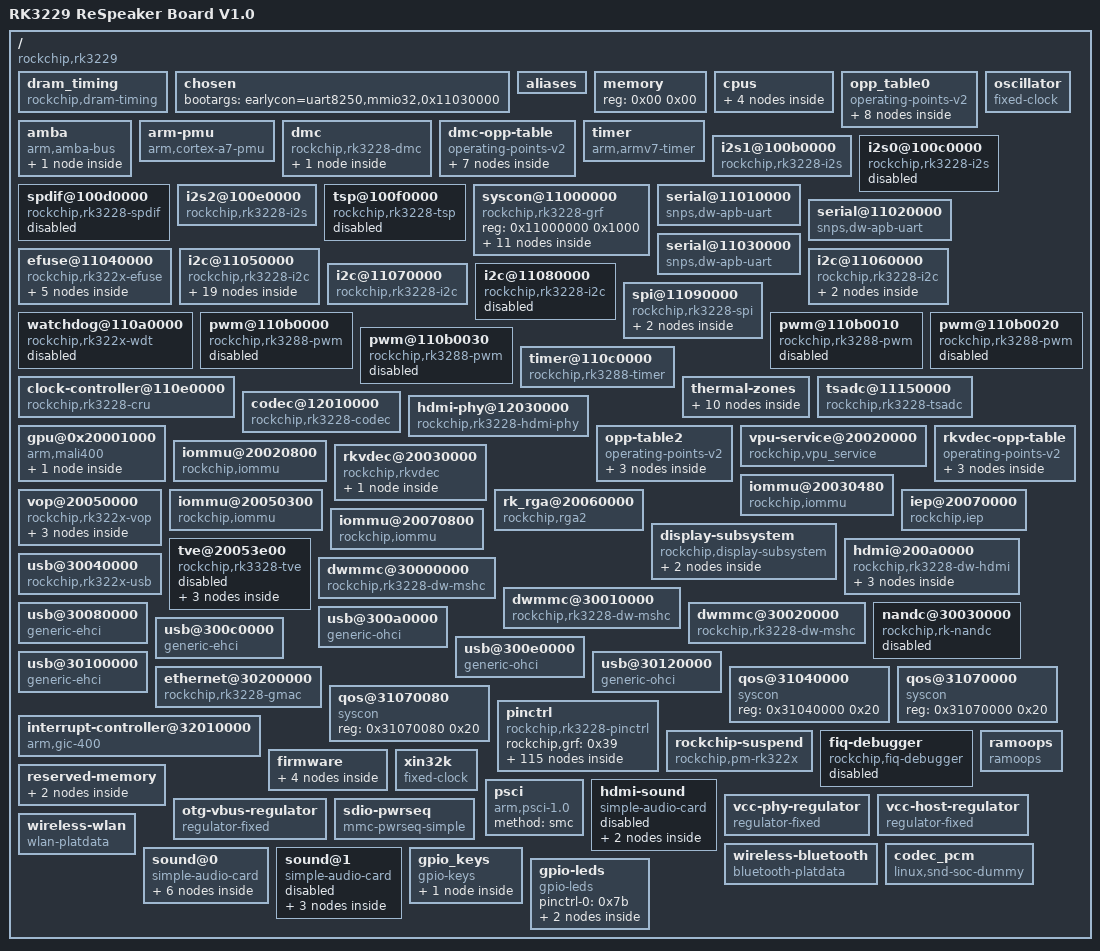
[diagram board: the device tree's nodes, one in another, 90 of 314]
/dts-v1/;

/ {
	#address-cells = <0x01>;
	#size-cells = <0x01>;
	interrupt-parent = <0x01>;
	model = "RK3229 ReSpeaker Board V1.0";
	compatible = "rockchip,rk3229";

	dram_timing {
		compatible = "rockchip,dram-timing";
		dram_spd_bin = <0x15>;
		sr_idle = <0x18>;
		pd_idle = <0x20>;
		dram_dll_disb_freq = <0x12c>;
		phy_dll_disb_freq = <0x190>;
		dram_odt_disb_freq = <0x14d>;
		phy_odt_disb_freq = <0x14d>;
		ddr3_drv = <0x00>;
		ddr3_odt = <0x40>;
		lpddr3_drv = <0x01>;
		lpddr3_odt = <0x03>;
		lpddr2_drv = <0x01>;
		phy_ddr3_clk_drv = <0x12>;
		phy_ddr3_cmd_drv = <0x12>;
		phy_ddr3_dqs_drv = <0x15>;
		phy_ddr3_odt = <0x02>;
		phy_lp23_clk_drv = <0x13>;
		phy_lp23_cmd_drv = <0x16>;
		phy_lp23_dqs_drv = <0x16>;
		phy_lp3_odt = <0x02>;
		phandle = <0x0b>;
	};

	chosen {
		bootargs = "earlycon=uart8250,mmio32,0x11030000";
	};

	aliases {
		serial0 = "/serial@11010000";
		serial1 = "/serial@11020000";
		serial2 = "/serial@11030000";
		spi0 = "/spi@11090000";
	};

	memory {
		device_type = "memory";
		reg = <0x00 0x00>;
	};

	cpus {
		#address-cells = <0x01>;
		#size-cells = <0x00>;

		cpu@f00 {
			device_type = "cpu";
			compatible = "arm,cortex-a7";
			reg = <0xf00>;
			resets = <0x02 0x04>;
			operating-points-v2 = <0x03>;
			#cooling-cells = <0x02>;
			dynamic-power-coefficient = <0x7a>;
			clock-latency = <0x9c40>;
			clocks = <0x02 0x05>;
			enable-method = "psci";
			cpu-supply = <0x04>;
			phandle = <0x06>;
		};

		cpu@f01 {
			device_type = "cpu";
			compatible = "arm,cortex-a7";
			reg = <0xf01>;
			resets = <0x02 0x05>;
			operating-points-v2 = <0x03>;
			enable-method = "psci";
			phandle = <0x07>;
		};

		cpu@f02 {
			device_type = "cpu";
			compatible = "arm,cortex-a7";
			reg = <0xf02>;
			resets = <0x02 0x06>;
			operating-points-v2 = <0x03>;
			enable-method = "psci";
			phandle = <0x08>;
		};

		cpu@f03 {
			device_type = "cpu";
			compatible = "arm,cortex-a7";
			reg = <0xf03>;
			resets = <0x02 0x07>;
			operating-points-v2 = <0x03>;
			enable-method = "psci";
			phandle = <0x09>;
		};
	};

	opp_table0 {
		compatible = "operating-points-v2";
		opp-shared;
		clocks = <0x02 0x01>;
		rockchip,max-volt = <0x149970>;
		rockchip,leakage-voltage-sel = <0x01 0x08 0x00 0x09 0xfe 0x01>;
		nvmem-cells = <0x05>;
		nvmem-cell-names = "cpu_leakage";
		phandle = <0x03>;

		opp-408000000 {
			opp-hz = <0x00 0x18519600>;
			opp-microvolt = <0xe7ef0 0xe7ef0 0x155cc0>;
			opp-microvolt-L0 = <0xe7ef0 0xe7ef0 0x155cc0>;
			opp-microvolt-L1 = <0xe7ef0 0xe7ef0 0x155cc0>;
			clock-latency-ns = <0x9c40>;
			opp-suspend;
		};

		opp-600000000 {
			opp-hz = <0x00 0x23c34600>;
			opp-microvolt = <0xee098 0xee098 0x155cc0>;
			opp-microvolt-L0 = <0xee098 0xee098 0x155cc0>;
			opp-microvolt-L1 = <0xee098 0xee098 0x155cc0>;
		};

		opp-816000000 {
			opp-hz = <0x00 0x30a32c00>;
			opp-microvolt = <0xf4240 0xf4240 0x155cc0>;
			opp-microvolt-L0 = <0xf4240 0xf4240 0x155cc0>;
			opp-microvolt-L1 = <0xf4240 0xf4240 0x155cc0>;
		};

		opp-1008000000 {
			opp-hz = <0x00 0x3c14dc00>;
			opp-microvolt = <0x11edd8 0x11edd8 0x155cc0>;
			opp-microvolt-L0 = <0x11edd8 0x11edd8 0x155cc0>;
			opp-microvolt-L1 = <0x112a88 0x112a88 0x155cc0>;
		};

		opp-1200000000 {
			opp-hz = <0x00 0x47868c00>;
			opp-microvolt = <0x137478 0x137478 0x155cc0>;
			opp-microvolt-L0 = <0x137478 0x137478 0x155cc0>;
			opp-microvolt-L1 = <0x12b128 0x12b128 0x155cc0>;
		};

		opp-1296000000 {
			opp-hz = <0x00 0x4d3f6400>;
			opp-microvolt = <0x1437c8 0x1437c8 0x155cc0>;
			opp-microvolt-L0 = <0x1437c8 0x1437c8 0x155cc0>;
			opp-microvolt-L1 = <0x137478 0x137478 0x155cc0>;
		};

		opp-1392000000 {
			opp-hz = <0x00 0x52f83c00>;
			opp-microvolt = <0x149970 0x149970 0x155cc0>;
			opp-microvolt-L0 = <0x149970 0x149970 0x155cc0>;
			opp-microvolt-L1 = <0x1437c8 0x1437c8 0x155cc0>;
		};

		opp-1464000000 {
			opp-hz = <0x00 0x5742de00>;
			opp-microvolt = <0x155cc0 0x155cc0 0x155cc0>;
			opp-microvolt-L0 = <0x155cc0 0x155cc0 0x155cc0>;
			opp-microvolt-L1 = <0x149970 0x149970 0x155cc0>;
		};
	};

	amba {
		compatible = "arm,amba-bus";
		#address-cells = <0x01>;
		#size-cells = <0x01>;
		ranges;

		pdma@110f0000 {
			compatible = "arm,pl330", "arm,primecell";
			reg = <0x110f0000 0x4000>;
			interrupts = <0x00 0x00 0x04 0x00 0x01 0x04>;
			#dma-cells = <0x01>;
			clocks = <0x02 0xc2>;
			clock-names = "apb_pclk";
			peripherals-req-type-burst;
			phandle = <0x0e>;
		};
	};

	arm-pmu {
		compatible = "arm,cortex-a7-pmu";
		interrupts = <0x00 0x4c 0x04 0x00 0x4d 0x04 0x00 0x4e 0x04 0x00 0x4f 0x04>;
		interrupt-affinity = <0x06 0x07 0x08 0x09>;
	};

	dmc {
		compatible = "rockchip,rk3228-dmc", "rockchip,rk322x-dram";
		clocks = <0x02 0x90>;
		clock-names = "dmc_clk";
		operating-points-v2 = <0x0a>;
		system-status-freq = <0x01 0x927c0 0x10 0xa2990 0x10000 0xbfe50>;
		dram_freq = <0x2ed96880>;
		rockchip,dram_timing = <0x0b>;
		#cooling-cells = <0x02>;
		status = "okay";
		center-supply = <0x0c>;
		phandle = <0x3d>;

		ddr_power_model {
			compatible = "ddr_power_model";
			dynamic-power-coefficient = <0x78>;
			static-power-coefficient = <0xc8>;
			ts = <0x7d00 0x125c 0xffffffb0 0x02>;
			thermal-zone = "soc-thermal";
		};
	};

	dmc-opp-table {
		compatible = "operating-points-v2";
		rockchip,leakage-voltage-sel = <0x01 0x05 0x00 0x06 0xfe 0x01>;
		nvmem-cells = <0x0d>;
		nvmem-cell-names = "ddr_leakage";
		phandle = <0x0a>;

		opp-300000000 {
			opp-hz = <0x00 0x11e1a300>;
			opp-microvolt = <0x100590>;
			opp-microvolt-L0 = <0x100590>;
			opp-microvolt-L1 = <0xf4240>;
		};

		opp-400000000 {
			opp-hz = <0x00 0x17d78400>;
			opp-microvolt = <0x100590>;
			opp-microvolt-L0 = <0x100590>;
			opp-microvolt-L1 = <0xf4240>;
		};

		opp-600000000 {
			opp-hz = <0x00 0x23c34600>;
			opp-microvolt = <0x10c8e0>;
			opp-microvolt-L0 = <0x10c8e0>;
			opp-microvolt-L1 = <0x100590>;
		};

		opp-666000000 {
			opp-hz = <0x00 0x27b25a80>;
			opp-microvolt = <0x118c30>;
			opp-microvolt-L0 = <0x118c30>;
			opp-microvolt-L1 = <0x10c8e0>;
		};

		opp-700000000 {
			opp-hz = <0x00 0x29b92700>;
			opp-microvolt = <0x118c30>;
			opp-microvolt-L0 = <0x118c30>;
			opp-microvolt-L1 = <0x10c8e0>;
		};

		opp-786000000 {
			opp-hz = <0x00 0x2ed96880>;
			opp-microvolt = <0x118c30>;
			opp-microvolt-L0 = <0x118c30>;
			opp-microvolt-L1 = <0x10c8e0>;
		};

		opp-800000000 {
			opp-hz = <0x00 0x2faf0800>;
			opp-microvolt = <0x118c30>;
			opp-microvolt-L0 = <0x118c30>;
			opp-microvolt-L1 = <0x10c8e0>;
		};
	};

	timer {
		compatible = "arm,armv7-timer";
		interrupts = <0x01 0x0d 0xf04 0x01 0x0e 0xf04 0x01 0x0b 0xf04 0x01 0x0a 0xf04>;
		clock-frequency = <0x16e3600>;
	};

	oscillator {
		compatible = "fixed-clock";
		clock-frequency = <0x16e3600>;
		clock-output-names = "xin24m";
		#clock-cells = <0x00>;
		phandle = <0x38>;
	};

	i2s1@100b0000 {
		compatible = "rockchip,rk3228-i2s", "rockchip,rk3066-i2s";
		reg = <0x100b0000 0x4000>;
		interrupts = <0x00 0x1b 0x04>;
		#address-cells = <0x01>;
		#size-cells = <0x00>;
		clock-names = "i2s_clk", "i2s_hclk";
		clocks = <0x02 0x51 0x02 0x1bb>;
		dmas = <0x0e 0x0e 0x0e 0x0f>;
		dma-names = "tx", "rx";
		pinctrl-names = "default";
		pinctrl-0 = <0x0f>;
		status = "okay";
		rockchip,i2s-broken-burst-len;
		rockchip,playback-channels = <0x02>;
		rockchip,bclk-fs = <0x40>;
		#sound-dai-cells = <0x00>;
		rockchip,bclk-en = <0x10 0x0b 0x00>;
		rockchip,capture-channels = <0x08>;
		phandle = <0x75>;
	};

	i2s0@100c0000 {
		compatible = "rockchip,rk3228-i2s", "rockchip,rk3066-i2s";
		reg = <0x100c0000 0x4000>;
		interrupts = <0x00 0x1a 0x04>;
		#address-cells = <0x01>;
		#size-cells = <0x00>;
		clock-names = "i2s_clk", "i2s_hclk";
		clocks = <0x02 0x50 0x02 0x1ba>;
		dmas = <0x0e 0x0b 0x0e 0x0c>;
		dma-names = "tx", "rx";
		status = "disabled";
		phandle = <0x6b>;
	};

	spdif@100d0000 {
		compatible = "rockchip,rk3228-spdif";
		reg = <0x100d0000 0x1000>;
		interrupts = <0x00 0x1d 0x04>;
		clocks = <0x02 0x53 0x02 0x1bd>;
		clock-names = "mclk", "hclk";
		dmas = <0x0e 0x0a>;
		#dma-cells = <0x01>;
		dma-names = "tx";
		pinctrl-names = "default";
		pinctrl-0 = <0x11>;
		status = "disabled";
	};

	i2s2@100e0000 {
		compatible = "rockchip,rk3228-i2s", "rockchip,rk3066-i2s";
		reg = <0x100e0000 0x4000>;
		interrupts = <0x00 0x1c 0x04>;
		#address-cells = <0x01>;
		#size-cells = <0x00>;
		clock-names = "i2s_clk", "i2s_hclk";
		clocks = <0x02 0x52 0x02 0x1bc>;
		dmas = <0x0e 0x00 0x0e 0x01>;
		dma-names = "tx", "rx";
		status = "okay";
		#sound-dai-cells = <0x00>;
		pinctrl-names = "default";
		pinctrl-0 = <0x12>;
		phandle = <0x78>;
	};

	tsp@100f0000 {
		compatible = "rockchip,rk3228-tsp";
		reg = <0x100f0000 0x10000>;
		interrupts = <0x00 0x48 0x04>;
		interrupt-names = "irq_tsp";
		clocks = <0x02 0x8b 0x02 0x1db 0x02 0x8c>;
		clock-names = "clk_tsp", "hclk_tsp", "aclk_tsp";
		pinctrl-names = "default";
		pinctrl-0 = <0x13 0x14 0x15 0x16 0x17 0x18 0x19 0x1a 0x1b 0x1c 0x1d 0x1e>;
		status = "disabled";
	};

	syscon@11000000 {
		compatible = "rockchip,rk3228-grf", "syscon", "simple-mfd";
		reg = <0x11000000 0x1000>;
		#address-cells = <0x01>;
		#size-cells = <0x01>;
		phandle = <0x39>;

		io-domains {
			compatible = "rockchip,rk322x-io-voltage-domain";
			status = "okay";
			vccio1-supply = <0x1f>;
			vccio2-supply = <0x1f>;
			vccio4-supply = <0x1f>;
		};

		reboot-mode {
			compatible = "syscon-reboot-mode";
			offset = <0x5c8>;
			mode-normal = <0x5242c300>;
			mode-recovery = <0x5242c303>;
			mode-loader = <0x5242c301>;
			mode-ums = <0x5242c30c>;
		};

		usb2-phy@760 {
			compatible = "rockchip,rk322x-usb2phy";
			reg = <0x760 0x0c>;
			clocks = <0x02 0x8e>;
			clock-names = "phyclk";
			#clock-cells = <0x00>;
			clock-output-names = "usb480m_phy0";
			status = "okay";
			phandle = <0x5f>;

			otg-port {
				#phy-cells = <0x00>;
				interrupts = <0x00 0x3b 0x04 0x00 0x3c 0x04 0x00 0x3d 0x04>;
				interrupt-names = "otg-bvalid", "otg-id", "linestate";
				status = "okay";
				vbus-supply = <0x20>;
				phandle = <0x5e>;
			};

			host-port {
				#phy-cells = <0x00>;
				interrupts = <0x00 0x3e 0x04>;
				interrupt-names = "linestate";
				status = "okay";
				phy-supply = <0x21>;
				phandle = <0x60>;
			};
		};

		usb2-phy@800 {
			compatible = "rockchip,rk322x-usb2phy";
			reg = <0x800 0x0c>;
			clocks = <0x02 0x8f>;
			clock-names = "phyclk";
			#clock-cells = <0x00>;
			clock-output-names = "usb480m_phy1";
			status = "okay";
			phandle = <0x61>;

			otg-port {
				#phy-cells = <0x00>;
				interrupts = <0x00 0x45 0x04>;
				interrupt-names = "linestate";
				status = "okay";
				phandle = <0x63>;
			};

			host-port {
				#phy-cells = <0x00>;
				interrupts = <0x00 0x44 0x04>;
				interrupt-names = "linestate";
				status = "okay";
				phy-supply = <0x21>;
				phandle = <0x62>;
			};
		};

		power-controller {
			compatible = "rockchip,rk3228-power-controller";
			#power-domain-cells = <0x01>;
			#address-cells = <0x01>;
			#size-cells = <0x00>;
			status = "okay";
			phandle = <0x43>;

			pd_vpu@6 {
				reg = <0x06>;
				clocks = <0x02 0xca 0x02 0x1d0>;
				pm_qos = <0x22>;
			};

			pd_rkvdec@7 {
				reg = <0x07>;
				clocks = <0x02 0xcb 0x02 0x1d1 0x02 0x85 0x02 0x86>;
				pm_qos = <0x23 0x24>;
			};
		};
	};

	serial@11010000 {
		compatible = "snps,dw-apb-uart";
		reg = <0x11010000 0x100>;
		interrupts = <0x00 0x37 0x04>;
		clock-frequency = <0x16e3600>;
		clocks = <0x02 0x4d 0x02 0x155>;
		clock-names = "baudclk", "apb_pclk";
		pinctrl-names = "default";
		pinctrl-0 = <0x25>;
		reg-shift = <0x02>;
		reg-io-width = <0x04>;
		status = "okay";
	};

	serial@11020000 {
		compatible = "snps,dw-apb-uart";
		reg = <0x11020000 0x100>;
		interrupts = <0x00 0x38 0x04>;
		clock-frequency = <0x16e3600>;
		clocks = <0x02 0x4e 0x02 0x156>;
		clock-names = "baudclk", "apb_pclk";
		pinctrl-names = "default";
		pinctrl-0 = <0x26 0x27>;
		reg-shift = <0x02>;
		reg-io-width = <0x04>;
		status = "okay";
	};

	serial@11030000 {
		compatible = "snps,dw-apb-uart";
		reg = <0x11030000 0x100>;
		interrupts = <0x00 0x39 0x04>;
		clock-frequency = <0x16e3600>;
		clocks = <0x02 0x4f 0x02 0x157>;
		clock-names = "baudclk", "apb_pclk";
		pinctrl-names = "default";
		pinctrl-0 = <0x28>;
		reg-shift = <0x02>;
		reg-io-width = <0x04>;
		status = "okay";
	};

	efuse@11040000 {
		compatible = "rockchip,rk322x-efuse";
		reg = <0x11040000 0x20>;
		#address-cells = <0x01>;
		#size-cells = <0x01>;
		clocks = <0x02 0x147>;
		clock-names = "pclk_efuse";

		id@7 {
			reg = <0x07 0x10>;
		};

		cpu_leakage@17 {
			reg = <0x17 0x01>;
			phandle = <0x05>;
		};

		logic-leakage@19 {
			reg = <0x19 0x01>;
			phandle = <0x0d>;
		};

		hdmi_phy_flag@1d {
			reg = <0x1d 0x01>;
			bits = <0x01 0x01>;
			phandle = <0x41>;
		};

		tve_dac@1d {
			reg = <0x1d 0x01>;
			bits = <0x03 0x05>;
			phandle = <0x52>;
		};
	};

	i2c@11050000 {
		compatible = "rockchip,rk3228-i2c";
		reg = <0x11050000 0x1000>;
		interrupts = <0x00 0x24 0x04>;
		#address-cells = <0x01>;
		#size-cells = <0x00>;
		clock-names = "i2c";
		clocks = <0x02 0x14c>;
		pinctrl-names = "default";
		pinctrl-0 = <0x29>;
		status = "okay";

		rk805@18 {
			compatible = "rockchip,rk805";
			status = "okay";
			reg = <0x18>;
			interrupt-parent = <0x2a>;
			interrupts = <0x01 0x08>;
			spinctrl-names = "default";
			pinctrl-0 = <0x2b>;
			rockchip,system-power-controller;
			wakeup-source;
			gpio-controller;
			#gpio-cells = <0x02>;
			#clock-cells = <0x01>;
			clock-output-names = "rk805-clkout1", "rk805-clkout2";
			phandle = <0x70>;

			rtc {
				status = "okay";
			};

			pwrkey {
				status = "okay";
			};

			gpio {
				status = "okay";
			};

			regulators {
				compatible = "rk805-regulator";
				status = "okay";
				#address-cells = <0x01>;
				#size-cells = <0x00>;

				RK805_DCDC1@0 {
					regulator-compatible = "RK805_DCDC1";
					regulator-name = "vdd_arm";
					regulator-min-microvolt = <0xadf34>;
					regulator-max-microvolt = <0x162010>;
					regulator-initial-mode = <0x01>;
					regulator-ramp-delay = <0x30d4>;
					regulator-boot-on;
					regulator-always-on;
					phandle = <0x04>;

					regulator-state-mem {
						regulator-mode = <0x02>;
						regulator-on-in-suspend;
						regulator-suspend-microvolt = <0xe7ef0>;
					};
				};

				RK805_DCDC2@1 {
					regulator-compatible = "RK805_DCDC2";
					regulator-name = "vdd_logic";
					regulator-min-microvolt = <0xadf34>;
					regulator-max-microvolt = <0x162010>;
					regulator-initial-mode = <0x01>;
					regulator-ramp-delay = <0x30d4>;
					regulator-boot-on;
					regulator-always-on;
					phandle = <0x0c>;

					regulator-state-mem {
						regulator-mode = <0x02>;
						regulator-on-in-suspend;
						regulator-suspend-microvolt = <0xf4240>;
					};
				};

				RK805_DCDC3@2 {
					regulator-compatible = "RK805_DCDC3";
					regulator-name = "vcc_ddr";
					regulator-initial-mode = <0x01>;
					regulator-boot-on;
					regulator-always-on;

					regulator-state-mem {
						regulator-mode = <0x02>;
						regulator-on-in-suspend;
					};
				};

				RK805_DCDC4@3 {
					regulator-compatible = "RK805_DCDC4";
					regulator-name = "vcc_io";
					regulator-min-microvolt = <0x325aa0>;
					regulator-max-microvolt = <0x325aa0>;
					regulator-initial-mode = <0x01>;
					regulator-boot-on;
					regulator-always-on;
					phandle = <0x1f>;

					regulator-state-mem {
						regulator-mode = <0x02>;
						regulator-on-in-suspend;
						regulator-suspend-microvolt = <0x325aa0>;
					};
				};

				RK805_LDO1@4 {
					regulator-compatible = "RK805_LDO1";
					regulator-name = "vcc_18";
					regulator-min-microvolt = <0x1b7740>;
					regulator-max-microvolt = <0x1b7740>;
					regulator-boot-on;
					regulator-always-on;

					regulator-state-mem {
						regulator-on-in-suspend;
						regulator-suspend-microvolt = <0x1b7740>;
					};
				};

				RK805_LDO2@5 {
					regulator-compatible = "RK805_LDO2";
					regulator-name = "vcc_18emmc";
					regulator-min-microvolt = <0x1b7740>;
					regulator-max-microvolt = <0x1b7740>;
					regulator-boot-on;
					regulator-always-on;

					regulator-state-mem {
						regulator-on-in-suspend;
						regulator-suspend-microvolt = <0x1b7740>;
					};
				};

				RK805_LDO3@6 {
					regulator-compatible = "RK805_LDO3";
					regulator-name = "vdd_10";
					regulator-min-microvolt = <0xf4240>;
					regulator-max-microvolt = <0xf4240>;
					regulator-boot-on;
					regulator-always-on;

					regulator-state-mem {
						regulator-on-in-suspend;
						regulator-suspend-microvolt = <0xf4240>;
					};
				};
			};
		};
	};

	i2c@11060000 {
		compatible = "rockchip,rk3228-i2c";
		reg = <0x11060000 0x1000>;
		interrupts = <0x00 0x25 0x04>;
		#address-cells = <0x01>;
		#size-cells = <0x00>;
		clock-names = "i2c";
		clocks = <0x02 0x14d>;
		pinctrl-names = "default";
		pinctrl-0 = <0x2c>;
		status = "okay";

		ac108@3b {
			#sound-dai-cells = <0x00>;
			compatible = "MicArray_0";
			reg = <0x3b>;
			rockchip,bclk-en = <0x10 0x0b 0x00>;
			phandle = <0x76>;
		};

		ac108@35 {
			#sound-dai-cells = <0x00>;
			compatible = "MicArray_1";
			rockchip,bclk-en = <0x10 0x0b 0x00>;
			reg = <0x35>;
		};
	};

	i2c@11070000 {
		compatible = "rockchip,rk3228-i2c";
		reg = <0x11070000 0x1000>;
		interrupts = <0x00 0x26 0x04>;
		#address-cells = <0x01>;
		#size-cells = <0x00>;
		clock-names = "i2c";
		clocks = <0x02 0x14e>;
		pinctrl-names = "default";
		pinctrl-0 = <0x2d>;
		status = "okay";
	};

	i2c@11080000 {
		compatible = "rockchip,rk3228-i2c";
		reg = <0x11080000 0x1000>;
		interrupts = <0x00 0x27 0x04>;
		#address-cells = <0x01>;
		#size-cells = <0x00>;
		clock-names = "i2c";
		clocks = <0x02 0x14f>;
		pinctrl-names = "default";
		pinctrl-0 = <0x2e>;
		status = "disabled";
	};

	spi@11090000 {
		compatible = "rockchip,rk3228-spi";
		reg = <0x11090000 0x1000>;
		interrupts = <0x00 0x31 0x04>;
		#address-cells = <0x01>;
		#size-cells = <0x00>;
		pinctrl-names = "default";
		pinctrl-0 = <0x2f 0x30 0x31 0x32 0x33>;
		clocks = <0x02 0x41 0x02 0x152>;
		clock-names = "spiclk", "apb_pclk";
		status = "okay";
		max-freq = <0x2dc6c00>;

		spi_slave@0 {
			compatible = "rockchip,spidev";
			reg = <0x00>;
			spi-max-frequency = <0xb71b00>;
		};

		spi_slave@1 {
			compatible = "rockchip,spidev";
			reg = <0x01>;
			spi-max-frequency = <0xb71b00>;
		};
	};

	watchdog@110a0000 {
		compatible = "rockchip,rk322x-wdt", "snps,dw-wdt";
		reg = <0x110a0000 0x100>;
		clocks = <0x02 0x162>;
		interrupts = <0x00 0x28 0x04>;
		status = "disabled";
	};

	pwm@110b0000 {
		compatible = "rockchip,rk3288-pwm";
		reg = <0x110b0000 0x10>;
		#pwm-cells = <0x03>;
		clocks = <0x02 0x15e>;
		clock-names = "pwm";
		pinctrl-names = "active";
		pinctrl-0 = <0x34>;
		status = "disabled";
	};

	pwm@110b0010 {
		compatible = "rockchip,rk3288-pwm";
		reg = <0x110b0010 0x10>;
		#pwm-cells = <0x03>;
		clocks = <0x02 0x15e>;
		clock-names = "pwm";
		pinctrl-names = "active";
		pinctrl-0 = <0x35>;
		status = "disabled";
	};

	pwm@110b0020 {
		compatible = "rockchip,rk3288-pwm";
		reg = <0x110b0020 0x10>;
		#pwm-cells = <0x03>;
		clocks = <0x02 0x15e>;
		clock-names = "pwm";
		pinctrl-names = "active";
		pinctrl-0 = <0x36>;
		status = "disabled";
	};

	pwm@110b0030 {
		compatible = "rockchip,rk3288-pwm";
		reg = <0x110b0030 0x10>;
		interrupts = <0x00 0x32 0x04>;
		#pwm-cells = <0x03>;
		clocks = <0x02 0x15e>;
		clock-names = "pwm";
		pinctrl-names = "active";
		pinctrl-0 = <0x37>;
		status = "disabled";
	};

	timer@110c0000 {
		compatible = "rockchip,rk3288-timer";
		reg = <0x110c0000 0x20>;
		interrupts = <0x00 0x2b 0x04>;
		clocks = <0x38 0x02 0x161>;
		clock-names = "timer", "pclk";
	};

	clock-controller@110e0000 {
		compatible = "rockchip,rk3228-cru";
		reg = <0x110e0000 0x1000>;
		rockchip,grf = <0x39>;
		#clock-cells = <0x01>;
		#reset-cells = <0x01>;
		assigned-clocks = <0x02 0x04 0x02 0x05 0x02 0x03 0x02 0xd2 0x02 0x1de 0x02 0x16b 0x02 0xc3 0x02 0x1cc 0x02 0x162 0x02 0xd3>;
		assigned-clock-rates = <0x47868c00 0x30a32c00 0x1dcd6500 0x8f0d180 0x8f0d180 0x47868c0 0x8f0d180 0x8f0d180 0x47868c0 0x17d78400>;
		phandle = <0x02>;
	};

	thermal-zones {

		soc-thermal {
			polling-delay-passive = <0x64>;
			polling-delay = <0x1388>;
			sustainable-power = <0x4b0>;
			thermal-sensors = <0x3a 0x00>;

			trips {

				trip-point@0 {
					temperature = <0x15f90>;
					hysteresis = <0x7d0>;
					type = "passive";
				};

				trip-point@1 {
					temperature = <0x19a28>;
					hysteresis = <0x7d0>;
					type = "passive";
					phandle = <0x3b>;
				};

				soc-crit {
					temperature = <0x1c138>;
					hysteresis = <0x7d0>;
					type = "critical";
				};
			};

			cooling-maps {

				map0 {
					trip = <0x3b>;
					cooling-device = <0x06 0xffffffff 0xffffffff>;
					contribution = <0x400>;
				};

				map1 {
					trip = <0x3b>;
					cooling-device = <0x3c 0xffffffff 0xffffffff>;
					contribution = <0x400>;
				};

				map2 {
					trip = <0x3b>;
					cooling-device = <0x3d 0xffffffff 0xffffffff>;
					contribution = <0x400>;
				};

				map3 {
					trip = <0x3b>;
					cooling-device = <0x3e 0xffffffff 0xffffffff>;
					contribution = <0x400>;
				};
			};
		};
	};

	tsadc@11150000 {
		compatible = "rockchip,rk3228-tsadc";
		reg = <0x11150000 0x100>;
		interrupts = <0x00 0x3a 0x04>;
		clocks = <0x02 0x48 0x02 0x158>;
		clock-names = "tsadc", "apb_pclk";
		assigned-clocks = <0x02 0x48>;
		assigned-clock-rates = <0x8000>;
		resets = <0x02 0x57>;
		reset-names = "tsadc-apb";
		pinctrl-names = "init", "default", "sleep";
		pinctrl-0 = <0x3f>;
		pinctrl-1 = <0x40>;
		pinctrl-2 = <0x3f>;
		#thermal-sensor-cells = <0x00>;
		rockchip,hw-tshut-temp = <0x1d4c0>;
		status = "okay";
		rockchip,hw-tshut-mode = <0x00>;
		phandle = <0x3a>;
	};

	codec@12010000 {
		compatible = "rockchip,rk3228-codec";
		reg = <0x12010000 0x1000>;
		clocks = <0x02 0x71 0x02 0x170 0x02 0x51>;
		clock-names = "mclk", "pclk", "sclk";
		spk-en-gpio = <0x2a 0x03 0x00>;
		status = "okay";
		#sound-dai-cells = <0x00>;
		phandle = <0x77>;
	};

	hdmi-phy@12030000 {
		compatible = "rockchip,rk3228-hdmi-phy";
		reg = <0x12030000 0x10000>;
		#phy-cells = <0x00>;
		clocks = <0x02 0x16d 0x38>;
		clock-names = "sysclk", "refclk";
		#clock-cells = <0x00>;
		clock-output-names = "hdmiphy_phy";
		nvmem-cells = <0x41>;
		nvmem-cell-names = "hdmi_phy_flag";
		status = "okay";
		phandle = <0x51>;
	};

	gpu@0x20001000 {
		compatible = "arm,mali400";
		reg = <0x20001000 0x200 0x20000000 0x100 0x20003000 0x100 0x20008000 0x1100 0x20004000 0x100 0x2000a000 0x1100 0x20005000 0x100>;
		reg-names = "Mali_L2", "Mali_GP", "Mali_GP_MMU", "Mali_PP0", "Mali_PP0_MMU", "Mali_PP1", "Mali_PP1_MMU";
		interrupts = <0x00 0x06 0x04 0x00 0x05 0x04 0x00 0x04 0x04 0x00 0x05 0x04 0x00 0x04 0x04 0x00 0x05 0x04>;
		interrupt-names = "Mali_GP_IRQ", "Mali_GP_MMU_IRQ", "Mali_PP0_IRQ", "Mali_PP0_MMU_IRQ", "Mali_PP1_IRQ", "Mali_PP1_MMU_IRQ";
		clocks = <0x02 0xd5>;
		#cooling-cells = <0x02>;
		clock-names = "clk_mali";
		operating-points-v2 = <0x42>;
		status = "okay";
		mali-supply = <0x0c>;
		phandle = <0x3c>;

		power_model {
			compatible = "arm,mali-simple-power-model";
			voltage = <0x384>;
			frequency = <0x1f4>;
			static-power = <0x12c>;
			dynamic-power = <0x18c>;
			ts = <0x7d00 0x125c 0xffffffb0 0x02>;
			thermal-zone = "soc-thermal";
		};
	};

	opp-table2 {
		compatible = "operating-points-v2";
		rockchip,leakage-voltage-sel = <0x01 0x05 0x00 0x06 0xfe 0x01>;
		nvmem-cells = <0x0d>;
		nvmem-cell-names = "gpu_leakage";
		phandle = <0x42>;

		opp-200000000 {
			opp-hz = <0x00 0xbebc200>;
			opp-microvolt = <0x100590>;
			opp-microvolt-L0 = <0x100590>;
			opp-microvolt-L1 = <0xf4240>;
		};

		opp-300000000 {
			opp-hz = <0x00 0x11e1a300>;
			opp-microvolt = <0x100590>;
			opp-microvolt-L0 = <0x100590>;
			opp-microvolt-L1 = <0xf4240>;
		};

		opp-500000000 {
			opp-hz = <0x00 0x1dcd6500>;
			opp-microvolt = <0x118c30>;
			opp-microvolt-L0 = <0x118c30>;
			opp-microvolt-L1 = <0x10c8e0>;
		};
	};

	vpu-service@20020000 {
		compatible = "rockchip,vpu_service";
		reg = <0x20020000 0x800>;
		interrupts = <0x00 0x09 0x04 0x00 0x0b 0x04>;
		interrupt-names = "irq_dec", "irq_enc";
		resets = <0x02 0x70 0x02 0x71>;
		reset-names = "video_a", "video_h";
		clocks = <0x02 0xca 0x02 0x1d0>;
		clock-names = "aclk_vcodec", "hclk_vcodec";
		power-domains = <0x43 0x06>;
		rockchip,grf = <0x39>;
		iommus = <0x44>;
		allocator = <0x01>;
		status = "okay";
	};

	iommu@20020800 {
		compatible = "rockchip,iommu";
		reg = <0x20020800 0x40>;
		interrupts = <0x00 0x0a 0x04>;
		interrupt-names = "vpu_mmu";
		clock-names = "aclk", "hclk";
		clocks = <0x02 0xca 0x02 0x1d0>;
		power-domains = <0x43 0x06>;
		#iommu-cells = <0x00>;
		status = "okay";
		phandle = <0x44>;
	};

	rkvdec@20030000 {
		compatible = "rockchip,rkvdec";
		reg = <0x20030000 0x400>;
		interrupts = <0x00 0x07 0x04>;
		interrupt-names = "irq_dec";
		clocks = <0x02 0xcb 0x02 0x1d1 0x02 0x85 0x02 0x86>;
		clock-names = "aclk_vcodec", "hclk_vcodec", "clk_cabac", "clk_core";
		resets = <0x02 0x76 0x02 0x78 0x02 0x77 0x02 0x79 0x02 0x7b 0x02 0x7a>;
		reset-names = "video_a", "video_h", "niu_a", "niu_h", "video_cabac", "video_core";
		power-domains = <0x43 0x07>;
		operating-points-v2 = <0x45>;
		#cooling-cells = <0x02>;
		rockchip,grf = <0x39>;
		iommus = <0x46>;
		allocator = <0x01>;
		status = "okay";
		phandle = <0x3e>;

		vcodec_power_model {
			compatible = "vcodec_power_model";
			dynamic-power-coefficient = <0x78>;
			static-power-coefficient = <0xc8>;
			ts = <0x7d00 0x125c 0xffffffb0 0x02>;
			thermal-zone = "soc-thermal";
		};
	};

	rkvdec-opp-table {
		compatible = "operating-points-v2";
		rockchip,leakage-voltage-sel = <0x01 0x05 0x00 0x06 0xfe 0x01>;
		nvmem-cells = <0x0d>;
		nvmem-cell-names = "rkvdec_leakage";
		phandle = <0x45>;

		opp-100000000 {
			opp-hz = <0x00 0x5f5e100>;
			opp-microvolt = <0x100590>;
			opp-microvolt-L0 = <0x100590>;
			opp-microvolt-L1 = <0xf4240>;
		};

		opp-200000000 {
			opp-hz = <0x00 0xbebc200>;
			opp-microvolt = <0x100590>;
			opp-microvolt-L0 = <0x100590>;
			opp-microvolt-L1 = <0xf4240>;
		};

		opp-500000000 {
			opp-hz = <0x00 0x1dcd6500>;
			opp-microvolt = <0x100590>;
			opp-microvolt-L0 = <0x100590>;
			opp-microvolt-L1 = <0xf4240>;
		};
	};

	iommu@20030480 {
		compatible = "rockchip,iommu";
		reg = <0x20030480 0x40 0x200304c0 0x40>;
		interrupts = <0x00 0x08 0x04>;
		interrupt-names = "rkvdec_mmu";
		clocks = <0x02 0xcb 0x02 0x1d1>;
		clock-names = "aclk", "hclk";
		power-domains = <0x43 0x07>;
		#iommu-cells = <0x00>;
		status = "okay";
		phandle = <0x46>;
	};

	vop@20050000 {
		compatible = "rockchip,rk322x-vop";
		reg = <0x20050000 0x1ffc>;
		reg-names = "regs";
		interrupts = <0x00 0x20 0x04>;
		clocks = <0x02 0xd3 0x02 0xbe 0x02 0x1c4>;
		clock-names = "aclk_vop", "dclk_vop", "hclk_vop";
		resets = <0x02 0x64 0x02 0x65 0x02 0x66>;
		reset-names = "axi", "ahb", "dclk";
		iommus = <0x47>;
		status = "okay";
		assigned-clocks = <0x02 0xbe>;
		assigned-clock-parents = <0x02 0xc0>;

		port {
			#address-cells = <0x01>;
			#size-cells = <0x00>;
			phandle = <0x4b>;

			endpoint@0 {
				reg = <0x00>;
				remote-endpoint = <0x48>;
				phandle = <0x4d>;
			};

			endpoint@1 {
				reg = <0x01>;
				remote-endpoint = <0x49>;
				phandle = <0x53>;
			};
		};
	};

	iommu@20050300 {
		compatible = "rockchip,iommu";
		reg = <0x20053f00 0x100>;
		interrupts = <0x00 0x20 0x04>;
		interrupt-names = "vop_mmu";
		clocks = <0x02 0xd3 0x02 0x1c4>;
		clock-names = "aclk", "hclk";
		#iommu-cells = <0x00>;
		status = "okay";
		phandle = <0x47>;
	};

	rk_rga@20060000 {
		compatible = "rockchip,rga2";
		reg = <0x20060000 0x1000>;
		interrupts = <0x00 0x21 0x04>;
		clocks = <0x02 0xcd 0x02 0x1d3 0x02 0x87>;
		clock-names = "aclk_rga", "hclk_rga", "clk_rga";
		dma-coherent;
		status = "okay";
	};

	iep@20070000 {
		compatible = "rockchip,iep";
		iommu_enabled = <0x01>;
		iommus = <0x4a>;
		reg = <0x20070000 0x800>;
		interrupts = <0x00 0x1f 0x04>;
		clocks = <0x02 0xcc 0x02 0x1d4>;
		clock-names = "aclk_iep", "hclk_iep";
		version = <0x03>;
		allocator = <0x01>;
		status = "okay";
	};

	iommu@20070800 {
		compatible = "rockchip,iommu";
		reg = <0x20070800 0x40>;
		interrupts = <0x00 0x1f 0x04>;
		interrupt-names = "iep_mmu";
		#iommu-cells = <0x00>;
		status = "okay";
		phandle = <0x4a>;
	};

	display-subsystem {
		compatible = "rockchip,display-subsystem";
		ports = <0x4b>;
		logo-memory-region = <0x4c>;
		status = "okay";

		route {

			route-hdmi {
				status = "okay";
				logo,uboot = "logo.bmp";
				logo,kernel = "logo_kernel.bmp";
				logo,mode = "center";
				charge_logo,mode = "center";
				connect = <0x4d>;
			};
		};
	};

	hdmi@200a0000 {
		compatible = "rockchip,rk3228-dw-hdmi";
		reg = <0x200a0000 0x20000>;
		reg-io-width = <0x04>;
		interrupts = <0x00 0x23 0x04 0x00 0x47 0x04>;
		clocks = <0x02 0x7b 0x02 0x16c 0x02 0x89>;
		clock-names = "isfr", "iahb", "cec";
		pinctrl-names = "default";
		pinctrl-0 = <0x4e 0x4f 0x50>;
		resets = <0x02 0x60>;
		reset-names = "hdmi";
		phys = <0x51>;
		phy-names = "hdmi_phy";
		rockchip,grf = <0x39>;
		status = "okay";
		#sound-dai-cells = <0x00>;
		ddc-i2c-scl-high-time-ns = <0x2599>;
		ddc-i2c-scl-low-time-ns = <0x2710>;
		phandle = <0x6c>;

		ports {

			port {
				#address-cells = <0x01>;
				#size-cells = <0x00>;

				endpoint@0 {
					reg = <0x00>;
					remote-endpoint = <0x4d>;
					phandle = <0x48>;
				};
			};
		};
	};

	tve@20053e00 {
		compatible = "rockchip,rk3328-tve";
		reg = <0x20053e00 0x100 0x12020000 0x10000>;
		rockchip,saturation = <0x305b46>;
		rockchip,brightcontrast = <0x9900>;
		rockchip,adjtiming = <0xd6c00880>;
		rockchip,lumafilter0 = <0x2ff0001>;
		rockchip,lumafilter1 = <0xf40200fe>;
		rockchip,lumafilter2 = <0xf332d910>;
		rockchip,daclevel = <0x15>;
		rockchip,dac1level = <0x07>;
		nvmem-cells = <0x52>;
		nvmem-cell-names = "tve_dac_adj";
		status = "disabled";

		ports {

			port {
				#address-cells = <0x01>;
				#size-cells = <0x00>;

				endpoint@0 {
					reg = <0x00>;
					remote-endpoint = <0x53>;
					phandle = <0x49>;
				};
			};
		};
	};

	dwmmc@30000000 {
		compatible = "rockchip,rk3228-dw-mshc", "rockchip,rk3288-dw-mshc";
		reg = <0x30000000 0x4000>;
		interrupts = <0x00 0x0c 0x04>;
		clocks = <0x02 0x1c8 0x02 0x44 0x02 0x72 0x02 0x76>;
		clock-names = "biu", "ciu", "ciu-drive", "ciu-sample";
		fifo-depth = <0x100>;
		pinctrl-names = "default";
		pinctrl-0 = <0x54 0x55 0x56>;
		status = "okay";
		bus-width = <0x04>;
		cap-sd-highspeed;
		card-detect-delay = <0xc8>;
		disable-wp;
		max-frequency = <0x2faf080>;
		num-slots = <0x01>;
		supports-sd;
	};

	dwmmc@30010000 {
		compatible = "rockchip,rk3228-dw-mshc", "rockchip,rk3288-dw-mshc";
		reg = <0x30010000 0x4000>;
		interrupts = <0x00 0x0d 0x04>;
		clocks = <0x02 0x1c9 0x02 0x45 0x02 0x73 0x02 0x77>;
		clock-names = "biu", "ciu", "ciu-drive", "ciu-sample";
		fifo-depth = <0x100>;
		pinctrl-names = "default";
		pinctrl-0 = <0x57 0x58 0x59>;
		status = "okay";
		bus-width = <0x04>;
		cap-mmc-highspeed;
		cap-sd-highspeed;
		cap-sdio-irq;
		non-removable;
		ignore-pm-notify;
		keep-power-in-suspend;
		max-frequency = <0x8f0d180>;
		supports-sdio;
		mmc-pwrseq = <0x5a>;
		num-slots = <0x01>;
		sd-uhs-sdr104;
	};

	dwmmc@30020000 {
		compatible = "rockchip,rk3228-dw-mshc", "rockchip,rk3288-dw-mshc";
		reg = <0x30020000 0x4000>;
		interrupts = <0x00 0x0e 0x04>;
		clock-frequency = <0x23c3460>;
		clock-freq-min-max = <0x61a80 0x23c3460>;
		clocks = <0x02 0x1cb 0x02 0x47 0x02 0x75 0x02 0x79>;
		clock-names = "biu", "ciu", "ciu-drive", "ciu-sample";
		bus-width = <0x08>;
		default-sample-phase = <0x9e>;
		num-slots = <0x01>;
		fifo-depth = <0x100>;
		pinctrl-names = "default";
		pinctrl-0 = <0x5b 0x5c 0x5d>;
		status = "okay";
		max-frequency = <0x2faf080>;
		broken-cd;
		cap-mmc-highspeed;
		sd-uhs-sdr50;
		supports-emmc;
		disable-wp;
		non-removable;
	};

	nandc@30030000 {
		compatible = "rockchip,rk-nandc";
		reg = <0x30030000 0x4000>;
		interrupts = <0x00 0x0f 0x04>;
		nandc_id = <0x00>;
		clocks = <0x02 0x43 0x02 0x1c5>;
		clock-names = "clk_nandc", "hclk_nandc";
		status = "disabled";
	};

	usb@30040000 {
		compatible = "rockchip,rk322x-usb", "rockchip,rk3066-usb", "snps,dwc2";
		reg = <0x30040000 0x40000>;
		interrupts = <0x00 0x17 0x04>;
		clocks = <0x02 0x1da>;
		clock-names = "otg";
		dr_mode = "otg";
		g-np-tx-fifo-size = <0x10>;
		g-rx-fifo-size = <0x118>;
		g-tx-fifo-size = <0x100 0x80 0x80 0x40 0x20 0x10>;
		g-use-dma;
		phys = <0x5e>;
		phy-names = "usb2-phy";
		status = "okay";
	};

	usb@30080000 {
		compatible = "generic-ehci";
		reg = <0x30080000 0x20000>;
		interrupts = <0x00 0x10 0x04>;
		clocks = <0x02 0x1d7 0x5f>;
		clock-names = "usbhost", "utmi";
		phys = <0x60>;
		phy-names = "usb";
		status = "okay";
	};

	usb@300a0000 {
		compatible = "generic-ohci";
		reg = <0x300a0000 0x20000>;
		interrupts = <0x00 0x11 0x04>;
		clocks = <0x02 0x1d7 0x5f>;
		clock-names = "usbhost", "utmi";
		phys = <0x60>;
		phy-names = "usb";
		status = "okay";
	};

	usb@300c0000 {
		compatible = "generic-ehci";
		reg = <0x300c0000 0x20000>;
		interrupts = <0x00 0x13 0x04>;
		clocks = <0x02 0x1d8 0x61>;
		clock-names = "usbhost", "utmi";
		phys = <0x62>;
		phy-names = "usb";
		status = "okay";
	};

	usb@300e0000 {
		compatible = "generic-ohci";
		reg = <0x300e0000 0x20000>;
		interrupts = <0x00 0x14 0x04>;
		clocks = <0x02 0x1d8 0x61>;
		clock-names = "usbhost", "utmi";
		phys = <0x62>;
		phy-names = "usb";
		status = "okay";
	};

	usb@30100000 {
		compatible = "generic-ehci";
		reg = <0x30100000 0x20000>;
		interrupts = <0x00 0x42 0x04>;
		clocks = <0x02 0x1d9 0x61>;
		phys = <0x63>;
		phy-names = "usb";
		clock-names = "usbhost", "utmi";
		status = "okay";
	};

	usb@30120000 {
		compatible = "generic-ohci";
		reg = <0x30120000 0x20000>;
		interrupts = <0x00 0x43 0x04>;
		clocks = <0x02 0x1d9 0x61>;
		clock-names = "usbhost", "utmi";
		phys = <0x63>;
		phy-names = "usb";
		status = "okay";
	};

	ethernet@30200000 {
		compatible = "rockchip,rk3228-gmac";
		reg = <0x30200000 0x10000>;
		interrupts = <0x00 0x18 0x04>;
		interrupt-names = "macirq";
		clocks = <0x02 0x7e 0x02 0x81 0x02 0x82 0x02 0x80 0x02 0x7f 0x02 0xd4 0x02 0x16f 0x02 0x83>;
		clock-names = "stmmaceth", "mac_clk_rx", "mac_clk_tx", "clk_mac_ref", "clk_mac_refout", "aclk_mac", "pclk_mac", "clk_macphy";
		resets = <0x02 0x38 0x02 0x3f>;
		reset-names = "stmmaceth", "mac-phy";
		rockchip,grf = <0x39>;
		status = "okay";
		assigned-clocks = <0x02 0x7c>;
		assigned-clock-rates = <0x2faf080>;
		clock_in_out = "output";
		phy-supply = <0x64>;
		phy-mode = "rmii";
		phy-is-integrated;
		pinctrl-names = "default";
		pinctrl-0 = <0x65>;
	};

	qos@31040000 {
		compatible = "syscon";
		reg = <0x31040000 0x20>;
		phandle = <0x22>;
	};

	qos@31070000 {
		compatible = "syscon";
		reg = <0x31070000 0x20>;
		phandle = <0x23>;
	};

	qos@31070080 {
		compatible = "syscon";
		reg = <0x31070080 0x20>;
		phandle = <0x24>;
	};

	interrupt-controller@32010000 {
		compatible = "arm,gic-400";
		interrupt-controller;
		#interrupt-cells = <0x03>;
		#address-cells = <0x00>;
		reg = <0x32011000 0x1000 0x32012000 0x2000 0x32014000 0x2000 0x32016000 0x2000>;
		interrupts = <0x01 0x09 0xf04>;
		phandle = <0x01>;
	};

	pinctrl {
		compatible = "rockchip,rk3228-pinctrl";
		rockchip,grf = <0x39>;
		#address-cells = <0x01>;
		#size-cells = <0x01>;
		ranges;
		pinctrl-names = "default";

		gpio0@11110000 {
			compatible = "rockchip,gpio-bank";
			reg = <0x11110000 0x100>;
			interrupts = <0x00 0x33 0x04>;
			clocks = <0x02 0x140>;
			gpio-controller;
			#gpio-cells = <0x02>;
			interrupt-controller;
			#interrupt-cells = <0x02>;
			phandle = <0x10>;
		};

		gpio1@11120000 {
			compatible = "rockchip,gpio-bank";
			reg = <0x11120000 0x100>;
			interrupts = <0x00 0x34 0x04>;
			clocks = <0x02 0x141>;
			gpio-controller;
			#gpio-cells = <0x02>;
			interrupt-controller;
			#interrupt-cells = <0x02>;
			phandle = <0x2a>;
		};

		gpio2@11130000 {
			compatible = "rockchip,gpio-bank";
			reg = <0x11130000 0x100>;
			interrupts = <0x00 0x35 0x04>;
			clocks = <0x02 0x142>;
			gpio-controller;
			#gpio-cells = <0x02>;
			interrupt-controller;
			#interrupt-cells = <0x02>;
			phandle = <0x72>;
		};

		gpio3@11140000 {
			compatible = "rockchip,gpio-bank";
			reg = <0x11140000 0x100>;
			interrupts = <0x00 0x36 0x04>;
			clocks = <0x02 0x143>;
			gpio-controller;
			#gpio-cells = <0x02>;
			interrupt-controller;
			#interrupt-cells = <0x02>;
			phandle = <0x6d>;
		};

		pcfg-pull-up {
			bias-pull-up;
			phandle = <0x69>;
		};

		pcfg-pull-down {
			bias-pull-down;
			phandle = <0x68>;
		};

		pcfg-pull-none {
			bias-disable;
			phandle = <0x67>;
		};

		pcfg-pull-none-drv-12ma {
			drive-strength = <0x0c>;
			phandle = <0x66>;
		};

		sdmmc {

			sdmmc-clk {
				rockchip,pins = <0x01 0x10 0x01 0x66>;
				phandle = <0x54>;
			};

			sdmmc-cmd {
				rockchip,pins = <0x01 0x0f 0x01 0x66>;
				phandle = <0x55>;
			};

			sdmmc-bus4 {
				rockchip,pins = <0x01 0x12 0x01 0x66 0x01 0x13 0x01 0x66 0x01 0x14 0x01 0x66 0x01 0x15 0x01 0x66>;
				phandle = <0x56>;
			};
		};

		sdio {

			sdio-clk {
				rockchip,pins = <0x03 0x00 0x01 0x66>;
				phandle = <0x57>;
			};

			sdio-cmd {
				rockchip,pins = <0x03 0x01 0x01 0x66>;
				phandle = <0x58>;
			};

			sdio-bus4 {
				rockchip,pins = <0x03 0x02 0x01 0x66 0x03 0x03 0x01 0x66 0x03 0x04 0x01 0x66 0x03 0x05 0x01 0x66>;
				phandle = <0x59>;
			};
		};

		emmc {

			emmc-clk {
				rockchip,pins = <0x02 0x07 0x02 0x67>;
				phandle = <0x5b>;
			};

			emmc-cmd {
				rockchip,pins = <0x01 0x16 0x02 0x67>;
				phandle = <0x5c>;
			};

			emmc-bus8 {
				rockchip,pins = <0x01 0x18 0x02 0x67 0x01 0x19 0x02 0x67 0x01 0x1a 0x02 0x67 0x01 0x1b 0x02 0x67 0x01 0x1c 0x02 0x67 0x01 0x1d 0x02 0x67 0x01 0x1e 0x02 0x67 0x01 0x1f 0x02 0x67>;
				phandle = <0x5d>;
			};
		};

		gmac {

			rgmii-pins {
				rockchip,pins = <0x02 0x0e 0x01 0x67 0x02 0x0c 0x01 0x67 0x02 0x19 0x01 0x67 0x02 0x13 0x01 0x66 0x02 0x12 0x01 0x66 0x02 0x16 0x01 0x66 0x02 0x17 0x01 0x66 0x02 0x09 0x01 0x66 0x02 0x0d 0x01 0x66 0x02 0x11 0x01 0x67 0x02 0x10 0x01 0x67 0x02 0x15 0x02 0x67 0x02 0x14 0x02 0x67 0x02 0x0b 0x01 0x67 0x02 0x08 0x01 0x67>;
			};

			rmii-pins {
				rockchip,pins = <0x02 0x0e 0x01 0x67 0x02 0x0c 0x01 0x67 0x02 0x19 0x01 0x67 0x02 0x13 0x01 0x66 0x02 0x12 0x01 0x66 0x02 0x0d 0x01 0x66 0x02 0x11 0x01 0x67 0x02 0x10 0x01 0x67 0x02 0x08 0x01 0x67 0x02 0x0f 0x01 0x67>;
			};

			phy-pins {
				rockchip,pins = <0x02 0x0e 0x02 0x67 0x02 0x08 0x02 0x67>;
				phandle = <0x65>;
			};
		};

		hdmi {

			hdmi-hpd {
				rockchip,pins = <0x00 0x0f 0x01 0x68>;
				phandle = <0x4f>;
			};

			hdmii2c-xfer {
				rockchip,pins = <0x00 0x06 0x02 0x67 0x00 0x07 0x02 0x67>;
				phandle = <0x4e>;
			};

			hdmi-cec {
				rockchip,pins = <0x00 0x14 0x01 0x67>;
				phandle = <0x50>;
			};
		};

		i2c0 {

			i2c0-xfer {
				rockchip,pins = <0x00 0x00 0x01 0x67 0x00 0x01 0x01 0x67>;
				phandle = <0x29>;
			};
		};

		i2c1 {

			i2c1-xfer {
				rockchip,pins = <0x00 0x02 0x01 0x67 0x00 0x03 0x01 0x67>;
				phandle = <0x2c>;
			};
		};

		i2c2 {

			i2c2-xfer {
				rockchip,pins = <0x02 0x14 0x01 0x67 0x02 0x15 0x01 0x67>;
				phandle = <0x2d>;
			};
		};

		i2c3 {

			i2c3-xfer {
				rockchip,pins = <0x00 0x06 0x01 0x67 0x00 0x07 0x01 0x67>;
				phandle = <0x2e>;
			};
		};

		tsp {

			tsp-d0 {
				rockchip,pins = <0x02 0x13 0x02 0x67>;
				phandle = <0x13>;
			};

			tsp-d1 {
				rockchip,pins = <0x02 0x12 0x02 0x67>;
				phandle = <0x14>;
			};

			tsp-d2 {
				rockchip,pins = <0x02 0x11 0x02 0x67>;
				phandle = <0x15>;
			};

			tsp-d3 {
				rockchip,pins = <0x02 0x10 0x02 0x67>;
				phandle = <0x16>;
			};

			tsp-d4 {
				rockchip,pins = <0x02 0x19 0x02 0x67>;
				phandle = <0x17>;
			};

			tsp-d5 {
				rockchip,pins = <0x02 0x18 0x02 0x67>;
				phandle = <0x18>;
			};

			tsp-d6 {
				rockchip,pins = <0x02 0x0f 0x02 0x67>;
				phandle = <0x19>;
			};

			tsp-d7 {
				rockchip,pins = <0x02 0x0d 0x02 0x67>;
				phandle = <0x1a>;
			};

			tsp-sync {
				rockchip,pins = <0x02 0x0c 0x02 0x67>;
				phandle = <0x1b>;
			};

			tsp-clk {
				rockchip,pins = <0x02 0x0b 0x02 0x67>;
				phandle = <0x1c>;
			};

			tsp-fail {
				rockchip,pins = <0x02 0x0a 0x02 0x67>;
				phandle = <0x1d>;
			};

			tsp-valid {
				rockchip,pins = <0x02 0x09 0x02 0x67>;
				phandle = <0x1e>;
			};
		};

		spi-0 {

			spi0-clk {
				rockchip,pins = <0x00 0x09 0x02 0x69>;
			};

			spi0-cs0 {
				rockchip,pins = <0x00 0x0e 0x02 0x69>;
			};

			spi0-tx {
				rockchip,pins = <0x00 0x0b 0x02 0x69>;
			};

			spi0-rx {
				rockchip,pins = <0x00 0x0d 0x02 0x69>;
			};

			spi0-cs1 {
				rockchip,pins = <0x01 0x0c 0x01 0x69>;
			};
		};

		spi-1 {

			spi1-clk {
				rockchip,pins = <0x00 0x17 0x02 0x69>;
				phandle = <0x2f>;
			};

			spi1-cs0 {
				rockchip,pins = <0x02 0x02 0x02 0x69>;
				phandle = <0x32>;
			};

			spi1-rx {
				rockchip,pins = <0x02 0x00 0x02 0x69>;
				phandle = <0x31>;
			};

			spi1-tx {
				rockchip,pins = <0x02 0x01 0x02 0x69>;
				phandle = <0x30>;
			};

			spi1-cs1 {
				rockchip,pins = <0x02 0x03 0x02 0x69>;
				phandle = <0x33>;
			};
		};

		i2s1 {

			i2s1-bus {
				rockchip,pins = <0x00 0x08 0x01 0x67 0x00 0x09 0x01 0x67 0x00 0x0c 0x01 0x67 0x00 0x0d 0x01 0x67 0x00 0x0e 0x01 0x67 0x01 0x02 0x02 0x67 0x01 0x04 0x02 0x67 0x01 0x05 0x02 0x67>;
				phandle = <0x0f>;
			};
		};

		pwm0 {

			pwm0-pin {
				rockchip,pins = <0x03 0x15 0x01 0x67>;
				phandle = <0x34>;
			};

			pwm0-pin-pull-down {
				rockchip,pins = <0x03 0x15 0x01 0x68>;
			};
		};

		pwm1 {

			pwm1-pin {
				rockchip,pins = <0x00 0x1e 0x02 0x67>;
				phandle = <0x35>;
			};

			pwm1-pin-pull-down {
				rockchip,pins = <0x00 0x1e 0x02 0x68>;
			};
		};

		pwm2 {

			pwm2-pin {
				rockchip,pins = <0x01 0x0c 0x02 0x67>;
				phandle = <0x36>;
			};

			pwm2-pin-pull-up {
				rockchip,pins = <0x01 0x0c 0x02 0x69>;
			};
		};

		pwm3 {

			pwm3-pin {
				rockchip,pins = <0x01 0x0b 0x02 0x67>;
				phandle = <0x37>;
			};

			pwm3-pin-pull-down {
				rockchip,pins = <0x01 0x0b 0x02 0x68>;
			};
		};

		spdif {

			spdif-tx {
				rockchip,pins = <0x03 0x1f 0x02 0x67>;
				phandle = <0x11>;
			};

			spdif-gpio {
				rockchip,pins = <0x03 0x1f 0x00 0x67>;
			};
		};

		tsadc {

			otp-gpio {
				rockchip,pins = <0x00 0x18 0x00 0x67>;
				phandle = <0x3f>;
			};

			otp-out {
				rockchip,pins = <0x00 0x18 0x02 0x67>;
				phandle = <0x40>;
			};
		};

		uart0 {

			uart0-xfer {
				rockchip,pins = <0x02 0x1a 0x01 0x67 0x02 0x1b 0x01 0x67>;
				phandle = <0x25>;
			};

			uart0-cts {
				rockchip,pins = <0x02 0x1d 0x01 0x67>;
			};

			uart0-rts {
				rockchip,pins = <0x00 0x11 0x01 0x67>;
			};
		};

		uart1 {

			uart1-xfer {
				rockchip,pins = <0x01 0x09 0x01 0x67 0x01 0x0a 0x01 0x67>;
			};

			uart1-cts {
				rockchip,pins = <0x01 0x08 0x01 0x67>;
			};

			uart1-rts {
				rockchip,pins = <0x01 0x0b 0x01 0x67>;
			};
		};

		uart1-1 {

			uart11-xfer {
				rockchip,pins = <0x03 0x0e 0x01 0x69 0x03 0x0d 0x01 0x67>;
				phandle = <0x26>;
			};

			uart11-cts {
				rockchip,pins = <0x03 0x07 0x01 0x67>;
				phandle = <0x27>;
			};

			uart11-rts {
				rockchip,pins = <0x03 0x06 0x01 0x67>;
				phandle = <0x73>;
			};

			uart11-rts-gpio {
				rockchip,pins = <0x03 0x06 0x00 0x67>;
				phandle = <0x74>;
			};
		};

		uart2 {

			uart2-xfer {
				rockchip,pins = <0x01 0x12 0x02 0x69 0x01 0x13 0x02 0x67>;
			};

			uart2-cts {
				rockchip,pins = <0x00 0x19 0x01 0x67>;
			};

			uart2-rts {
				rockchip,pins = <0x00 0x18 0x01 0x67>;
			};
		};

		uart2-1 {

			uart21-xfer {
				rockchip,pins = <0x01 0x0a 0x02 0x69 0x01 0x09 0x02 0x67>;
				phandle = <0x28>;
			};
		};

		pmic {

			pmic-int-l {
				rockchip,pins = <0x01 0x0c 0x00 0x69>;
				phandle = <0x2b>;
			};
		};

		pcm {

			pcm-io {
				rockchip,pins = <0x00 0x1a 0x02 0x67 0x00 0x1b 0x02 0x67 0x03 0x0b 0x01 0x67 0x03 0x0c 0x01 0x67>;
				phandle = <0x12>;
			};
		};

		usb {

			host-vbus-drv {
				rockchip,pins = <0x03 0x14 0x00 0x67>;
				phandle = <0x6e>;
			};

			otg-vbus-drv {
				rockchip,pins = <0x03 0x16 0x00 0x67>;
				phandle = <0x6f>;
			};
		};

		ir {

			ir-gpio {
				rockchip,pins = <0x01 0x0b 0x00 0x69>;
			};
		};

		sdio-pwrseq {

			wifi-enable-h {
				rockchip,pins = <0x02 0x1a 0x00 0x67>;
				phandle = <0x71>;
			};
		};

		keys {

			user-key {
				rockchip,pins = <0x03 0x19 0x00 0x69>;
				phandle = <0x7a>;
			};
		};

		gpio {

			gpio-leds {
				rockchip,pins = <0x01 0x07 0x00 0x67 0x03 0x15 0x00 0x67>;
				phandle = <0x7b>;
			};
		};
	};

	rockchip-suspend {
		compatible = "rockchip,pm-rk322x";
		status = "okay";
		rockchip,virtual-poweroff = <0x00>;
		rockchip,sleep-mode-config = <0x10042>;
	};

	fiq-debugger {
		compatible = "rockchip,fiq-debugger";
		interrupts = <0x00 0x51 0x04>;
		rockchip,serial-id = <0x02>;
		rockchip,signal-irq = <0x9f>;
		rockchip,wake-irq = <0x00>;
		rockchip,irq-mode-enable = <0x00>;
		rockchip,baudrate = <0x1c200>;
		pinctrl-names = "default";
		pinctrl-0 = <0x28>;
		status = "disabled";
	};

	firmware {

		android {
			compatible = "android,firmware";

			fstab {
				compatible = "android,fstab";

				system {
					compatible = "android,system";
					dev = "/dev/block/by-name/system";
					type = "ext4";
					mnt_flags = "ro,barrier=1,inode_readahead_blks=8";
					fsmgr_flags = "wait,verify";
				};

				vendor {
					compatible = "android,vendor";
					dev = "/dev/block/by-name/vendor";
					type = "ext4";
					mnt_flags = "ro,barrier=1,inode_readahead_blks=8";
					fsmgr_flags = "wait,verify";
				};
			};
		};
	};

	reserved-memory {
		#address-cells = <0x01>;
		#size-cells = <0x01>;
		ranges;

		drm-logo@00000000 {
			compatible = "rockchip,drm-logo";
			reg = <0x00 0x00>;
			phandle = <0x4c>;
		};

		ramoops@62e00000 {
			reg = <0x62e00000 0xf0000>;
			phandle = <0x6a>;
		};
	};

	ramoops {
		compatible = "ramoops";
		record-size = <0x00 0x20000>;
		console-size = <0x00 0x80000>;
		ftrace-size = <0x00 0x00>;
		pmsg-size = <0x00 0x50000>;
		memory-region = <0x6a>;
	};

	xin32k {
		compatible = "fixed-clock";
		clock-frequency = <0x8000>;
		clock-output-names = "xin32k";
		#clock-cells = <0x00>;
	};

	psci {
		compatible = "arm,psci-1.0";
		method = "smc";
	};

	hdmi-sound {
		status = "disabled";
		compatible = "simple-audio-card";
		simple-audio-card,format = "i2s";
		simple-audio-card,mclk-fs = <0x100>;
		simple-audio-card,name = "rockchip,hdmi";

		simple-audio-card,cpu {
			sound-dai = <0x6b>;
		};

		simple-audio-card,codec {
			sound-dai = <0x6c>;
		};
	};

	vcc-phy-regulator {
		compatible = "regulator-fixed";
		enable-active-high;
		regulator-name = "vcc_phy";
		regulator-min-microvolt = <0x1b7740>;
		regulator-max-microvolt = <0x1b7740>;
		regulator-always-on;
		regulator-boot-on;
		phandle = <0x64>;
	};

	vcc-host-regulator {
		compatible = "regulator-fixed";
		enable-active-high;
		gpio = <0x6d 0x14 0x00>;
		pinctrl-names = "default";
		pinctrl-0 = <0x6e>;
		regulator-name = "vcc_host";
		regulator-always-on;
		regulator-boot-on;
		phandle = <0x21>;
	};

	otg-vbus-regulator {
		compatible = "regulator-fixed";
		gpio = <0x6d 0x16 0x00>;
		pinctrl-names = "default";
		pinctrl-0 = <0x6f>;
		regulator-name = "vcc_otg_vbus";
		regulator-min-microvolt = <0x4c4b40>;
		regulator-max-microvolt = <0x4c4b40>;
		enable-active-high;
		phandle = <0x20>;
	};

	sdio-pwrseq {
		compatible = "mmc-pwrseq-simple";
		clocks = <0x70 0x01>;
		clock-names = "ext_clock";
		pinctrl-names = "default";
		pinctrl-0 = <0x71>;
		reset-gpios = <0x72 0x1a 0x01>;
		phandle = <0x5a>;
	};

	wireless-bluetooth {
		compatible = "bluetooth-platdata";
		clocks = <0x70 0x01>;
		clock-names = "ext_clock";
		uart_rts_gpios = <0x6d 0x06 0x01>;
		pinctrl-names = "default", "rts_gpio";
		pinctrl-0 = <0x73>;
		pinctrl-1 = <0x74>;
		BT,reset_gpio = <0x72 0x1d 0x00>;
		BT,wake_gpio = <0x6d 0x1b 0x00>;
		BT,wake_host_irq = <0x6d 0x1a 0x00>;
		status = "okay";
	};

	wireless-wlan {
		compatible = "wlan-platdata";
		rockchip,grf = <0x39>;
		wifi_chip_type = "ap6212";
		sdio_vref = <0x708>;
		WIFI,host_wake_irq = <0x10 0x1c 0x00>;
		status = "okay";
	};

	codec_pcm {
		compatible = "linux,snd-soc-dummy";
		#sound-dai-cells = <0x00>;
		phandle = <0x79>;
	};

	sound@0 {
		compatible = "simple-audio-card";
		simple-audio-card,name = "seeed-8mic-voicecard";
		simple-audio-card,mclk-fs = <0x100>;
		status = "okay";

		simple-audio-card,dai-link@0 {
			format = "i2s";

			cpu {
				sound-dai = <0x75>;
			};

			codec {
				sound-dai = <0x76>;
			};
		};

		simple-audio-card,dai-link@1 {
			format = "i2s";

			cpu {
				sound-dai = <0x75>;
			};

			codec {
				sound-dai = <0x77>;
			};
		};
	};

	sound@1 {
		compatible = "simple-audio-card";
		simple-audio-card,name = "bluetooth-a2dp";
		simple-audio-card,mclk-fs = <0x100>;
		status = "disabled";

		simple-audio-card,dai-link@0 {
			format = "i2s";

			cpu {
				sound-dai = <0x78>;
				system-clock-frequency = <0x16e3600>;
			};

			codec {
				system-clock-frequency = <0x16e3600>;
				sound-dai = <0x79>;
			};
		};
	};

	gpio_keys {
		compatible = "gpio-keys";
		#address-cells = <0x01>;
		#size-cells = <0x00>;
		autorepeat;
		pinctrl-names = "default";
		pinctrl-0 = <0x7a>;

		key-1 {
			label = "GPIO User Key";
			gpios = <0x6d 0x19 0x01>;
			linux,code = <0xc2>;
			debounce-interval = <0x64>;
			wakeup-source;
		};
	};

	gpio-leds {
		compatible = "gpio-leds";
		pinctrl-names = "default";
		pinctrl-0 = <0x7b>;

		heartbeat {
			gpios = <0x2a 0x07 0x01>;
			label = "respeaker2:blue:state1";
			linux,default-trigger = "heartbeat";
			default-state = "off";
		};

		mmc {
			gpios = <0x6d 0x15 0x01>;
			label = "respeaker2:blue:state2";
			linux,default-trigger = "mmc0";
			default-state = "off";
		};
	};
};
